# f29h85x_pipe_regs register map
Vendor: Texas Instruments
Peripheral module from a debugger description file (folder C29).
Registers are 32-bit, read-write, no defined reset value unless marked. A register's access mark holds for its fields unless they carry their own. Offsets are as the file gives them; lines under a group give offsets from that group; [hi:lo] are bit positions; {n}, {i} and the like mark numbered series; 'fields as' and 'values as' point back to an identical list; <NAME> marks a mode.

## PIPE_REGS — PIPE Registers
0x00 RTINT_THRESHOLD — Interrupt threshold register
  [7:0] INT_RTINT_THRESHOLD — Interrupt threshold value
0x04 INT_GRP_MASK — Interrupt group mask register
  [7:0] INT_GRP_MASK — Interrupt group mask
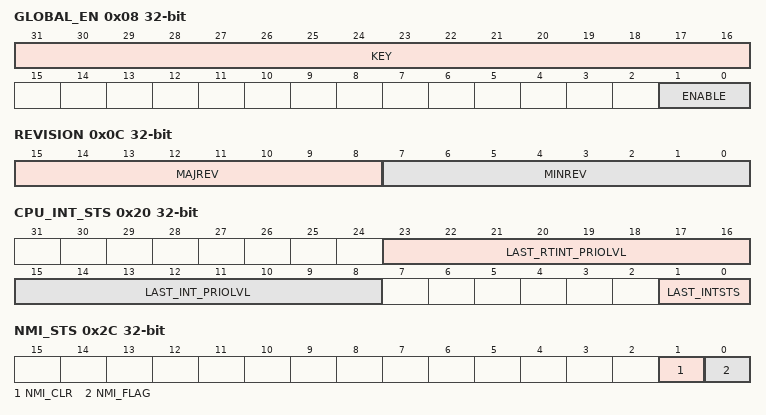
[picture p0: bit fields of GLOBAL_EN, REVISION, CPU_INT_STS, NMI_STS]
0x08 GLOBAL_EN — Global enable for INT and RTINT
  [31:16] KEY — Key to enable write to lower [15:0] bit fields
  [1:0] ENABLE — Global enable
0x0C REVISION ro — Reserved
  [15:8] MAJREV — Major Revision Number
  [7:0] MINREV — Minor Revision Number
0x20 CPU_INT_STS ro — CPU interrupt status
  [23:16] LAST_RTINT_PRIOLVL — Priority level of last RTINT interrupt in-service
  [15:8] LAST_INT_PRIOLVL — Priority level of last INT interrupt in-service
  [1:0] LAST_INTSTS — Type of last interrupt in-service between INT and RTINT
0x24 RST_VECT ro — Reset vector register
  [31:0] VECT — Reset vector location
0x28 RST_LINK_OWNER ro — Reset link owner register
  [3:0] LINK_OWNER — Reset vector link owner
0x2C NMI_STS access per field — Non Maskable Interrupt status register
  [1] NMI_CLR rw — NMI SW clear bit
  [0] NMI_FLAG ro — Interrupt active
0x30 NMI_VECT — Non Maskable Interrupt vector register
  [31:0] VECT — NMI vector location
0x34 NMI_LINK_OWNER — Non Maskable Interrupt link owner register
  [3:0] LINK_OWNER — NMI vector link owner
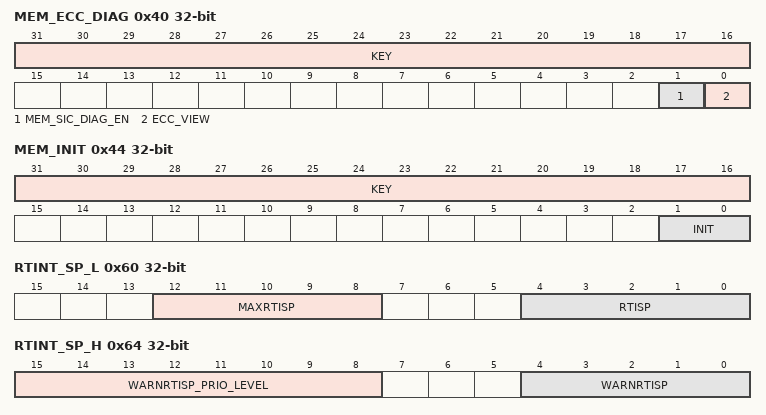
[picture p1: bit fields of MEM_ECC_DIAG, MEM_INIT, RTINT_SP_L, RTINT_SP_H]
0x40 MEM_ECC_DIAG — ECC diagnostics register
  [31:16] KEY — Key to enable write to lower [15:0] bit fields
  [1] MEM_SIC_DIAG_EN — Memory safe interconnect diagnostics enable
  [0] ECC_VIEW — ECC memory map enable register
0x44 MEM_INIT — PIPE vector memory initialization register
  [31:16] KEY — Key to enable write to lower [15:0] bit fields
  [1:0] INIT — Memory initialization start
0x48 MEM_INIT_STS ro — PIPE memory initialization status register
  [1:0] INIT_STS — Memory initialization status
0x4C INT_SEC_STS ro — Interrupt security status register
  [0] SEC_FAIL_FLAG — VBUSP access security error
0x50 INT_SEC_CLR — Interrupt security clear register
  [0] SEC_FAIL_FLAG_CLR — SEC_FAIL_FLAG bit clear field
0x60 RTINT_SP_L ro — RTINT stack limit register
  [12:8] MAXRTISP — Maximum Real Time Interrupt Stack Pointer
  [4:0] RTISP — Real Time Interrupt Stack Pointer
0x64 RTINT_SP_H — RTINT stack limit register
  [15:8] WARNRTISP_PRIO_LEVEL — RTINT Stack Pointer warning priority level
  [4:0] WARNRTISP — Warning Real Time Interrupt Stack Pointer
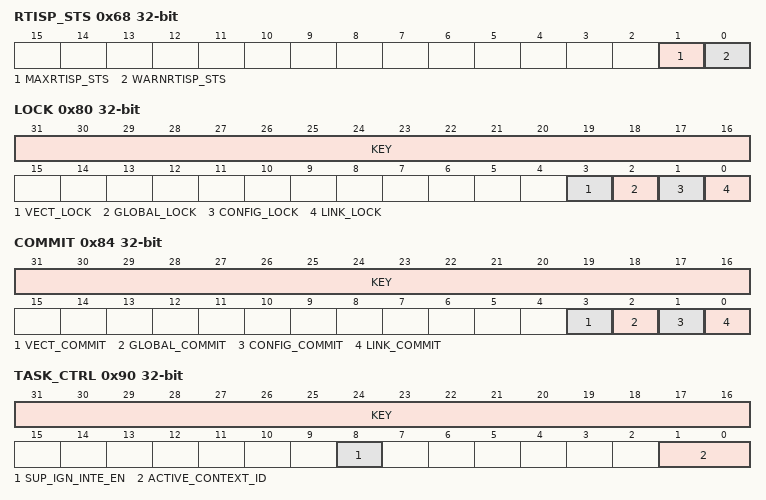
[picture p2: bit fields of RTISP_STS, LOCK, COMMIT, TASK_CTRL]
0x68 RTISP_STS ro — RTINT Stack pointer violation status register
  [1] MAXRTISP_STS — RTINT Stack Pointer max breach status
  [0] WARNRTISP_STS — RTINT Stack Pointer warning status
0x6C INTSP — INT stack pointer
  [3:0] INTSP — INT Interrupt Stack
0x80 LOCK — PIPE lock register
  [31:16] KEY — Key to enable write to lower [15:0] bit fields
  [3] VECT_LOCK — Lock bit for Vector memory
  [2] GLOBAL_LOCK — Lock bit for common config regs
  [1] CONFIG_LOCK — Lock bit for interrupt priority field
  [0] LINK_LOCK — Lock bit for link owner field
0x84 COMMIT — PIPE commit register
  [31:16] KEY — Key to enable write to lower [15:0] bit fields
  [3] VECT_COMMIT — Commit bit for vector memory
  [2] GLOBAL_COMMIT — Commit bit for common config regs
  [1] CONFIG_COMMIT — Commit bit for interrupt priority field
  [0] LINK_COMMIT — Commit bit for link fields
0x90 TASK_CTRL — Task control register
  [31:16] KEY — Key to enable write to lower [15:0] bit fields
  [8] SUP_IGN_INTE_EN — Supervisor Interrupt Enable
  [1:0] ACTIVE_CONTEXT_ID — Active context ID for PIPE arbitration.
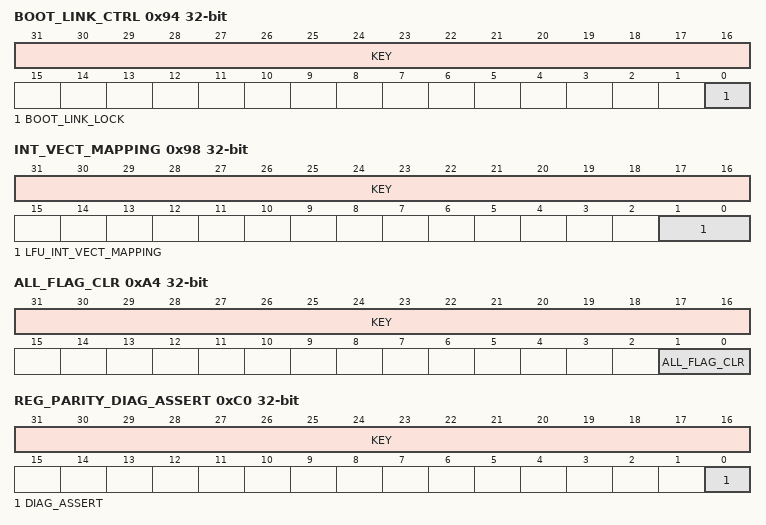
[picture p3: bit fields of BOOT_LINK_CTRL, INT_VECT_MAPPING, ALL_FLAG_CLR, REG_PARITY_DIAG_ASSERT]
0x94 BOOT_LINK_CTRL — Boot Link control to lock out BOOT_LINK
  [31:16] KEY — Key to enable write to lower [15:0] bit fields
  [0] BOOT_LINK_LOCK — Locks the Boot Link updates to configuration registers.
0x98 INT_VECT_MAPPING — Interrupt vector mapping for LFU, FOTA, and INT vector swapping support
  [31:16] KEY — Key to enable write to lower [15:0] bit fields
  [1:0] LFU_INT_VECT_MAPPING — Interrupt vector mapping to PPB for LFU support
0xA0 MMR_CLR — PIPE MMR clear register
  [1:0] MMR_CLR — PIPE MMR clear control
0xA4 ALL_FLAG_CLR — PIPE flag clear register
  [31:16] KEY — Key to enable write to lower [15:0] bit fields
  [1:0] ALL_FLAG_CLR — Clears the Flags for all the interrupt lines.
0xB0 REG_PARITY_DIAG_DATA — Register parity Diagnostic data
  [31:0] DIAG_DATA — Diagnostics data
0xB8 REG_PARITY_DIAG_PARITY — Register parity Diagnostic Parity
  [3:0] DIAG_PARITY_DATA — Diagnostics parity data
0xC0 REG_PARITY_DIAG_ASSERT — Register parity Assert diagnostic
  [31:16] KEY — Key to enable write to lower [15:0] bit fields
  [0] DIAG_ASSERT — Diagnostics assert
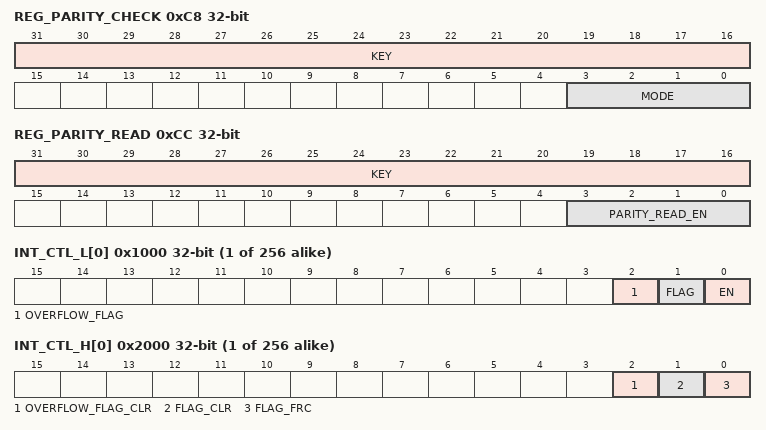
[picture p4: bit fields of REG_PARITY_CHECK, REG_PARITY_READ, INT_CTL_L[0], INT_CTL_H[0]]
0xC8 REG_PARITY_CHECK — Enabling the Parity check
  [31:16] KEY — Key to enable write to lower [15:0] bit fields
  [3:0] MODE — Parity check mode
0xCC REG_PARITY_READ — Enabling the Parity read
  [31:16] KEY — Key to enable write to lower [15:0] bit fields
  [3:0] PARITY_READ_EN — Parity read enable
{0x1000+4i} INT_CTL_L[{i}] (i=0..255) access per field — Interrupt low flag and status control register
  [2] OVERFLOW_FLAG ro — INT_OVERFLOW_FLAG status
  [1] FLAG ro — INT FLAG status
  [0] EN rw — INT enable
{0x2000+4i} INT_CTL_H[{i}] (i=0..255) — Interrupt high flag and status control register
  [2] OVERFLOW_FLAG_CLR — INT_OVERFLOW_FLAG clear bit
  [1] FLAG_CLR — INT_FLAG clear bit
  [0] FLAG_FRC — INT SW set bit
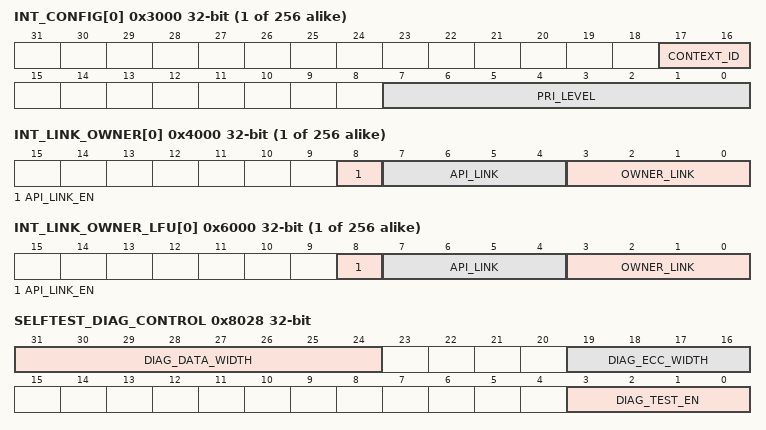
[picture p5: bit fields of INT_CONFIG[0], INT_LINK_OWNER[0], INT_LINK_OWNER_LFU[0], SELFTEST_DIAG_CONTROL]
{0x3000+4i} INT_CONFIG[{i}] (i=0..255) — Interrupt configuration register
  [17:16] CONTEXT_ID — Interrupt Context-ID
  [7:0] PRI_LEVEL — Priority level
{0x4000+4i} INT_LINK_OWNER[{i}] (i=0..255) — Interrupt link ownership config register
  [8] API_LINK_EN — Access protection inheritance link enable for INT
  [7:4] API_LINK — Access protection inheritance link for INT
  [3:0] OWNER_LINK — Link owner for INT
{0x5000+4i} INT_VECT_ADDR[{i}] (i=0..255) — Interrupt vector address
  [31:0] VECT_ADDR — INT vector address
{0x6000+4i} INT_LINK_OWNER_LFU[{i}] (i=0..255) — Interrupt link ownership config register
  [8] API_LINK_EN — Access protection inheritance link enable for INT for LFU
  [7:4] API_LINK — Access protection inheritance link for INT for LFU
  [3:0] OWNER_LINK — Link owner for INT for LFU
{0x7000+4i} INT_VECT_ADDR_LFU[{i}] (i=0..255) — Interrupt vector address
  [31:0] VECT_ADDR — INT vector address for LFU
0x8000 SELFTEST_DIAG_DATA0 — Diagnostics data register 0
  [31:0] SELFTEST_DIAG_DATA0 — Self test Diagnostics data 0
0x8004 SELFTEST_DIAG_DATA1 — Diagnostics data register 1
  [19:0] SELFTEST_DIAG_DATA1 — Self test Diagnostics data 1
0x8020 SELFTEST_DIAG_ECC — Diagnostics ECC
  [6:0] SELFTEST_DIAG_ECC — Self test Diagnostics ECC
0x8028 SELFTEST_DIAG_CONTROL — Diagnostic test enable.
  [31:24] DIAG_DATA_WIDTH — Diagnostic Data width
  [19:16] DIAG_ECC_WIDTH — Diagnostic ECC width
  [3:0] DIAG_TEST_EN — Diagnostic test enable
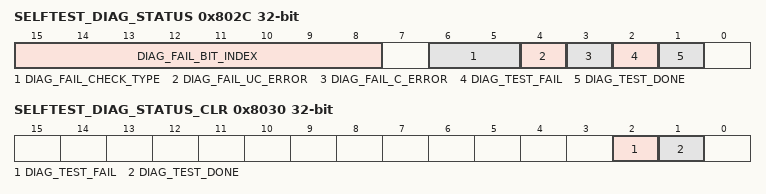
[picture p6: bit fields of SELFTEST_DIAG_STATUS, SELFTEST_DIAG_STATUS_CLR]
0x802C SELFTEST_DIAG_STATUS ro — Diagnostic status register
  [15:8] DIAG_FAIL_BIT_INDEX — Error bit position
  [6:5] DIAG_FAIL_CHECK_TYPE — Failed diagnostic check type
  [4] DIAG_FAIL_UC_ERROR — Diagnostic uncorrectable error
  [3] DIAG_FAIL_C_ERROR — Diagnostic correctable error
  [2] DIAG_TEST_FAIL — Test failed
  [1] DIAG_TEST_DONE — Done self test
0x8030 SELFTEST_DIAG_STATUS_CLR — Diagnostic status clear register
  [2] DIAG_TEST_FAIL — Clear test failed status flags
  [1] DIAG_TEST_DONE — Clear self test done status flag
